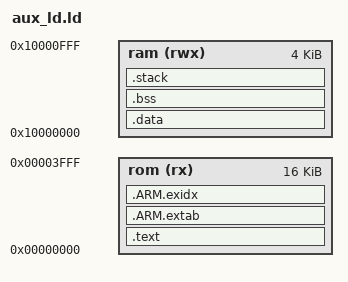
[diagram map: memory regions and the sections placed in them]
OUTPUT_FORMAT ("elf32-littlearm", "elf32-bigarm", "elf32-littlearm")

MEMORY
{
	rom (rx)  :   ORIGIN = 0x00000000, LENGTH = 16K
	ram (rwx) :   ORIGIN = 0x10000000, LENGTH = 4K
}

SECTIONS
{
	.text :
	{
		KEEP(*(.isr_vector))
		*(.text*)
		
		KEEP(*(.init))
		KEEP(*(.fini))
		
		/* .ctors */
		*crtbegin.o(.ctors)
		*crtbegin?.o(.ctors)
		*(EXCLUDE_FILE(*crtend?.o *crtend.o) .ctors)
		*(SORT(.ctors.*))
		*(.ctors)
		
		/* .dtors */
		*crtbegin.o(.dtors)
		*crtbegin?.o(.dtors)
		*(EXCLUDE_FILE(*crtend?.o *crtend.o) .dtors)
		*(SORT(.dtors.*))
		*(.dtors)
		
		*(.rodata*)
		
		KEEP(*(.eh_fram e*))
	} > rom 
	
	.ARM.extab : 
	{
		*(.ARM.extab* .gnu.linkonce.armextab.*)
	} > rom 
	
	.ARM.exidx :
	{
		*(.ARM.exidx* .gnu.linkonce.armexidx.*)
	} > rom 
	
	. = ALIGN(4);
	_etext = .;
	
	_sidata = _etext;
	
	.data : AT (_sidata)
	{
		_sdata = .;
		
		*(vtable)
		*(.data*)
		
		. = ALIGN(4);
		PROVIDE_HIDDEN (__preinit_array_start = .);
		KEEP(*(.preinit_array))
		PROVIDE_HIDDEN (__preinit_array_end = .);
		
		. = ALIGN(4);
		PROVIDE_HIDDEN (__init_array_start = .);
		KEEP(*(SORT(.init_array.*)))
		KEEP(*(.init_array))
		PROVIDE_HIDDEN (__init_array_end = .);
		
		. = ALIGN(4);
		PROVIDE_HIDDEN (__fini_array_start = .);
		KEEP(*(SORT(.fini_array.*)))
		KEEP(*(.fini_array))
		PROVIDE_HIDDEN (__fini_array_end = .);
		
		KEEP(*(.jcr*))
		. = ALIGN(4);

		_edata = .;
	} > ram 
	
	.bss :
	{
		. = ALIGN(4);
		_sbss = .;
		*(.bss*)
		*(COMMON)
		. = ALIGN(4);
		_ebss = .;
	} > ram 
	
	.stack (NOLOAD):
	{
		. = ALIGN(8);
		*(.stack .stack.*)
	} > ram 

	ASSERT((ORIGIN(rom) + LENGTH(rom)) >= (_etext + SIZEOF(.data)), "region rom overflowed")
	ASSERT(LENGTH(ram) >= (ADDR(.stack) + SIZEOF(.stack)), "region ram overflowed")
}
